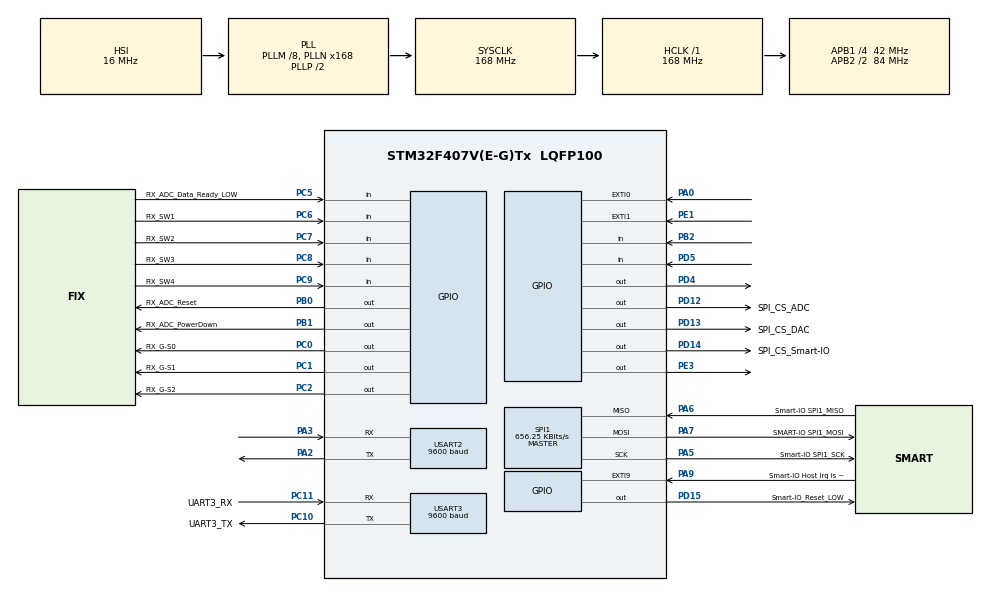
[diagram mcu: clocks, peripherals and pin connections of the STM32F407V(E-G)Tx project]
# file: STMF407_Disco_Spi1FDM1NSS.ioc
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Mcu.Family=STM32F4
Mcu.Name=STM32F407V(E-G)Tx
Mcu.Package=LQFP100
NVIC.EXTI0_IRQn=true\:0\:0\:false\:true\:true\:1\:true
NVIC.EXTI1_IRQn=true\:0\:0\:false\:true\:true\:2\:true
NVIC.PriorityGroup=NVIC_PRIORITYGROUP_0
NVIC.SPI1_IRQn=true\:0\:0\:false\:true\:true\:4\:true
NVIC.TIM2_IRQn=true\:0\:0\:false\:true\:true\:3\:true
PA0-WKUP.GPIO_ModeDefaultEXTI=GPIO_MODE_IT_RISING
PA0-WKUP.GPIO_PuPd=GPIO_NOPULL
PA0-WKUP.Signal=GPXTI0
PA10.GPIO_Mode=GPIO_MODE_AF_PP
PA10.GPIO_PuPd=GPIO_NOPULL
PA10.GPIO_Speed=GPIO_SPEED_FREQ_VERY_HIGH
PA10.Signal=USB_OTG_FS_ID
PA11.GPIO_Mode=GPIO_MODE_AF_PP
PA11.GPIO_PuPd=GPIO_NOPULL
PA11.GPIO_Speed=GPIO_SPEED_FREQ_VERY_HIGH
PA11.Signal=USB_OTG_FS_DM
PA12.GPIO_Mode=GPIO_MODE_AF_PP
PA12.GPIO_PuPd=GPIO_NOPULL
PA12.GPIO_Speed=GPIO_SPEED_FREQ_VERY_HIGH
PA12.Signal=USB_OTG_FS_DP
PA13.GPIO_Label=SerialWireDebug_IO
PA13.Mode=Serial_Wire
PA13.Signal=SYS_JTMS-SWDIO
PA14.GPIO_Label=SerialWireDebug_CLK
PA14.Mode=Serial_Wire
PA14.Signal=SYS_JTCK-SWCLK
PA15.Signal=S_TIM2_CH1_ETR
PA2.Mode=Asynchronous
PA2.Signal=USART2_TX
PA3.Mode=Asynchronous
PA3.Signal=USART2_RX
PA4.GPIO_Mode=GPIO_MODE_AF_PP
PA4.GPIO_PuPd=GPIO_NOPULL
PA4.GPIO_Speed=GPIO_SPEED_FREQ_LOW
PA4.Signal=I2S3_WS
PA5.GPIO_Label=Smart-IO SPI1_SCK
PA5.Mode=Full_Duplex_Master
PA5.Signal=SPI1_SCK
PA6.GPIO_Label=Smart-IO SPI1_MISO
PA6.GPIO_Mode=GPIO_MODE_AF_PP
PA6.GPIO_PuPd=GPIO_NOPULL
PA6.GPIO_Speed=GPIO_SPEED_FREQ_VERY_HIGH
PA6.Mode=Full_Duplex_Master
PA6.Signal=SPI1_MISO
PA7.GPIO_Label=SMART-IO SPI1_MOSI
PA7.GPIO_Mode=GPIO_MODE_AF_PP
PA7.GPIO_PuPd=GPIO_NOPULL
PA7.GPIO_Speed=GPIO_SPEED_FREQ_VERY_HIGH
PA7.Mode=Full_Duplex_Master
PA7.Signal=SPI1_MOSI
PA9.GPIO_Label=Smart-IO Host Irq is LOW
PA9.GPIO_ModeDefaultEXTI=GPIO_MODE_IT_RISING
PA9.Signal=GPXTI9
PB0.GPIO_Label=FIX_ADC_Reset
PB0.Signal=GPIO_Output
PB1.GPIO_Label=FIX_ADC_PowerDown
PB1.Signal=GPIO_Output
PB10.GPIO_Mode=GPIO_MODE_AF_PP
PB10.GPIO_PuPd=GPIO_NOPULL
PB10.GPIO_Speed=GPIO_SPEED_FREQ_LOW
PB10.Signal=I2S2_CK
PB11.Signal=I2C2_SDA
PB2.GPIO_Mode=GPIO_MODE_INPUT
PB2.GPIO_PuPd=GPIO_NOPULL
PB2.Signal=GPIO_Input
PB3.GPIO_Label=SerialWireDebug_SWO
PB3.Signal=SYS_JTDO-SWO
PB4.Signal=SYS_JTRST
PB6.Signal=I2C1_SCL
PB7.Signal=I2C1_SDA
PC0.GPIO_Label=FIX_G-S0
PC0.GPIO_ModeDefaultOutputPP=GPIO_MODE_OUTPUT_PP
PC0.GPIO_PuPd=GPIO_NOPULL
PC0.GPIO_Speed=GPIO_SPEED_FREQ_LOW
PC0.PinState=GPIO_PIN_RESET
PC0.Signal=GPIO_Output
PC1.GPIO_Label=FIX_G-S1
PC1.Signal=GPIO_Output
PC10.GPIO_Label=UART3_TX
PC10.Mode=Asynchronous
PC10.Signal=USART3_TX
PC11.GPIO_Label=UART3_RX
PC11.Mode=Asynchronous
PC11.Signal=USART3_RX
PC12.GPIO_Mode=GPIO_MODE_AF_PP
PC12.GPIO_PuPd=GPIO_NOPULL
PC12.GPIO_Speed=GPIO_SPEED_FREQ_LOW
PC12.Signal=I2S3_SD
PC2.GPIO_Label=FIX_G-S2
PC2.Signal=GPIO_Output
PC3.GPIO_Mode=GPIO_MODE_AF_PP
PC3.GPIO_PuPd=GPIO_NOPULL
PC3.GPIO_Speed=GPIO_SPEED_FREQ_LOW
PC3.Signal=I2S2_SD
PC5.GPIO_Label=FIX_ADC_Data_Ready_LOW
PC5.Signal=GPIO_Input
PC6.GPIO_Label=FIX_SW1
PC6.Signal=GPIO_Input
PC7.GPIO_Label=FIX_SW2
PC7.Signal=GPIO_Input
PC8.GPIO_Label=FIX_SW3
PC8.Signal=GPIO_Input
PC9.GPIO_Label=FIX_SW4
PC9.Signal=GPIO_Input
PD12.GPIO_Label=SPI_CS_ADC
PD12.GPIO_ModeDefaultOutputPP=GPIO_MODE_OUTPUT_PP
PD12.GPIO_PuPd=GPIO_NOPULL
PD12.GPIO_Speed=GPIO_SPEED_FREQ_LOW
PD12.PinState=GPIO_PIN_RESET
PD12.Signal=GPIO_Output
PD13.GPIO_Label=SPI_CS_DAC
PD13.GPIO_ModeDefaultOutputPP=GPIO_MODE_OUTPUT_PP
PD13.GPIO_PuPd=GPIO_NOPULL
PD13.GPIO_Speed=GPIO_SPEED_FREQ_LOW
PD13.PinState=GPIO_PIN_RESET
PD13.Signal=GPIO_Output
PD14.GPIO_Label=SPI_CS_Smart-IO
PD14.GPIO_ModeDefaultOutputPP=GPIO_MODE_OUTPUT_PP
PD14.GPIO_PuPd=GPIO_NOPULL
PD14.GPIO_Speed=GPIO_SPEED_FREQ_LOW
PD14.PinState=GPIO_PIN_RESET
PD14.Signal=GPIO_Output
PD15.GPIO_Label=Smart-IO_Reset_LOW
PD15.GPIO_ModeDefaultOutputPP=GPIO_MODE_OUTPUT_PP
PD15.GPIO_PuPd=GPIO_NOPULL
PD15.GPIO_Speed=GPIO_SPEED_FREQ_LOW
PD15.PinState=GPIO_PIN_SET
PD15.Signal=GPIO_Output
PD4.GPIO_ModeDefaultOutputPP=GPIO_MODE_OUTPUT_PP
PD4.GPIO_PuPd=GPIO_NOPULL
PD4.GPIO_Speed=GPIO_SPEED_FREQ_LOW
PD4.PinState=GPIO_PIN_RESET
PD4.Signal=GPIO_Output
PD5.GPIO_Mode=GPIO_MODE_INPUT
PD5.GPIO_PuPd=GPIO_NOPULL
PD5.Signal=GPIO_Input
PE1.GPIO_ModeDefaultEXTI=GPIO_MODE_IT_RISING
PE1.GPIO_PuPd=GPIO_NOPULL
PE1.Signal=GPXTI1
PE3.GPIO_ModeDefaultOutputPP=GPIO_MODE_OUTPUT_PP
PE3.GPIO_PuPd=GPIO_NOPULL
PE3.GPIO_Speed=GPIO_SPEED_FREQ_LOW
PE3.PinState=GPIO_PIN_RESET
PE3.Signal=GPIO_Output
PH0-OSC_IN.Signal=RCC_OSC_IN
PH1-OSC_OUT.Signal=RCC_OSC_OUT
ProjectManager.HeapSize=0x200
ProjectManager.StackSize=0x400
ProjectManager.TargetToolchain=EWARM
RCC.48MHZClocksFreq_Value=48000000
RCC.AHBFreq_Value=168000000
RCC.APB1CLKDivider=RCC_HCLK_DIV4
RCC.APB1Freq_Value=42000000
RCC.APB1TimFreq_Value=84000000
RCC.APB2CLKDivider=RCC_HCLK_DIV2
RCC.APB2Freq_Value=84000000
RCC.APB2TimFreq_Value=168000000
RCC.CortexFreq_Value=168000000
RCC.HCLKFreq_Value=168000000
RCC.HSE_VALUE=8000000
RCC.HSI_VALUE=16000000
RCC.LSE_VALUE=32768
RCC.PLLM=8
RCC.PLLN=168
RCC.PLLQ=7
RCC.SYSCLKFreq_VALUE=168000000
RCC.SYSCLKSource=RCC_SYSCLKSOURCE_PLLCLK
RCC.VCOOutputFreq_Value=336000000
SH.S_TIM2_CH1_ETR.0=TIM2_CH1
SPI1.BaudRatePrescaler=SPI_BAUDRATEPRESCALER_128
SPI1.CalculateBaudRate=656.25 KBits/s
SPI1.Direction=SPI_DIRECTION_2LINES
SPI1.Mode=SPI_MODE_MASTER
SPI1.VirtualType=VM_MASTER
TIM2.ClockDivision=TIM_CLOCKDIVISION_DIV4
TIM2.Prescaler=0
USART2.BaudRate=9600
USART2.VirtualMode=VM_ASYNC
USART3.BaudRate=9600
USART3.VirtualMode=VM_ASYNC
VP_RTC_VS_RTC_Activate.Mode=RTC_Enabled
VP_RTC_VS_RTC_Calendar.Mode=RTC_Calendar
VP_TIM1_VS_ClockSourceINT.Mode=Internal
VP_TIM2_VS_ClockSourceINT.Mode=Internal
VP_TIM3_VS_ClockSourceINT.Mode=Internal
board=STM32F4DISCOVERY

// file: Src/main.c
/**
  ******************************************************************************
  * @file           : main.c
  * @brief          : Main program body
  ******************************************************************************
  ** This notice applies to any and all portions of this file
  * that are not between comment pairs USER CODE BEGIN and
  * USER CODE END. Other portions of this file, whether
  * inserted by the user or by software development tools
  * are owned by their respective copyright owners.
  *
  * COPYRIGHT(c) 2018 STMicroelectronics
  *
  * Redistribution and use in source and binary forms, with or without modification,
  * are permitted provided that the following conditions are met:
  *   1. Redistributions of source code must retain the above copyright notice,
  *      this list of conditions and the following disclaimer.
  *   2. Redistributions in binary form must reproduce the above copyright notice,
  *      this list of conditions and the following disclaimer in the documentation
  *      and/or other materials provided with the distribution.
  *   3. Neither the name of STMicroelectronics nor the names of its contributors
  *      may be used to endorse or promote products derived from this software
  *      without specific prior written permission.
  *
  * THIS SOFTWARE IS PROVIDED BY THE COPYRIGHT HOLDERS AND CONTRIBUTORS "AS IS"
  * AND ANY EXPRESS OR IMPLIED WARRANTIES, INCLUDING, BUT NOT LIMITED TO, THE
  * IMPLIED WARRANTIES OF MERCHANTABILITY AND FITNESS FOR A PARTICULAR PURPOSE ARE
  * DISCLAIMED. IN NO EVENT SHALL THE COPYRIGHT HOLDER OR CONTRIBUTORS BE LIABLE
  * FOR ANY DIRECT, INDIRECT, INCIDENTAL, SPECIAL, EXEMPLARY, OR CONSEQUENTIAL
  * DAMAGES (INCLUDING, BUT NOT LIMITED TO, PROCUREMENT OF SUBSTITUTE GOODS OR
  * SERVICES; LOSS OF USE, DATA, OR PROFITS; OR BUSINESS INTERRUPTION) HOWEVER
  * CAUSED AND ON ANY THEORY OF LIABILITY, WHETHER IN CONTRACT, STRICT LIABILITY,
  * OR TORT (INCLUDING NEGLIGENCE OR OTHERWISE) ARISING IN ANY WAY OUT OF THE USE
  * OF THIS SOFTWARE, EVEN IF ADVISED OF THE POSSIBILITY OF SUCH DAMAGE.
  *
  ******************************************************************************
  */
#include "main.h"
#include "stm32f4xx_hal.h"
#include "rtc.h"
#include "spi.h"
#include "tim.h"
#include "usart.h"
#include "gpio.h"

/* USER CODE BEGIN Includes */
//#include "Smart-IO.main
/* USER CODE END Includes */

/* USER CODE BEGIN PV */
/* Private variables ---------------------------------------------------------*/
uint8_t txArray_9[9] = "abcTest\n\r";
/* USER CODE END PV */

void SystemClock_Config(void);
static void MX_NVIC_Init(void);

/* USER CODE BEGIN PFP */
/* Private function prototypes -----------------------------------------------*/

/* USER CODE END PFP */

int main(void)
{
  /* USER CODE BEGIN 1 */
//FISH_STM32F4_CONFIG_DEFINES.h
  /* USER CODE END 1 */

  /* MCU Configuration----------------------------------------------------------*/

  /* Reset of all peripherals, Initializes the Flash interface and the Systick. */
  HAL_Init();

  /* Configure the system clock */
  SystemClock_Config();

  /* USER CODE BEGIN SysInit */
  // In the MX_"PERIPH"_Init() calls below:

  // MX_USART2_UART_Init(); Creates UART_HandleTypeDef huart2; Smart_IO commamds
  // MX_USART3_UART_Init(); Creates UART_HandleTypeDef huart3; FISH

  // MX_SPI1_Init(); Creates SPI_HandleTypeDef  hspi;
  // It's name can't be changed - overwritten by CubeMX.
  /*
      I have to verify settings and make my own and call after if so.
      And verify clock is giving me the required Smart-IO Clock and
      the other spi devices needs.
      STM NSS is not used. SPI chip select is software managed.
      NSS on SPI1 forces SWD vs JTAG.
  */

  /* USER CODE END SysInit */

  /* Initialize all configured peripherals */
  MX_GPIO_Init();
  MX_USART3_UART_Init();
  MX_SPI1_Init();
  MX_TIM1_Init();
  MX_TIM2_Init();
  MX_TIM3_Init();
  MX_RTC_Init();
  MX_USART2_UART_Init();

  /* Initialize interrupts */
  MX_NVIC_Init();
  /* USER CODE BEGIN 2 */
/*

  * @brief  Sends an amount of data in non blocking mode.
  * @param  huart pointer to a UART_HandleTypeDef structure that contains
  *                the configuration information for the specified UART module.
  * @param  pData Pointer to data buffer
  * @param  Size Amount of data to be sent
  * @retval HAL status
HAL_StatusTypeDef HAL_UART_Transmit_IT(UART_HandleTypeDef *huart, uint8_t *pData, uint16_t Size)
*/
  HAL_UART_Transmit_IT(&huart3, "Test\n\r", 6);
  HAL_UART_Transmit_IT(&huart3, txArray_9, 9);
  Smart_IO_main();

/* (@) From stm32f4xx_hal_spi.c: The max SPI frequency depend on SPI data size (8bits, 16bits),
       SPI mode(2 Lines fullduplex, 2 lines RxOnly, 1 line TX/RX) and Process mode (Polling, IT, DMA).
   (@)
        (+@) TX/RX processes are HAL_SPI_TransmitReceive(), HAL_SPI_TransmitReceive_IT() and HAL_SPI_TransmitReceive_DMA()
        (+@) RX processes are HAL_SPI_Receive(), HAL_SPI_Receive_IT() and HAL_SPI_Receive_DMA()
        (+@) TX processes are HAL_SPI_Transmit(), HAL_SPI_Transmit_IT() and HAL_SPI_Transmit_DMA()
*/
/* (@) If we use the F4 Discovery board use the LED's for debug/system status */
/* (#) Declare a SPI_HandleTypeDef handle structure, for example: */
/*        SPI_HandleTypeDef  hspi;
          or
          SPI_HandleTypeDef  SmartIO_hal_spi_handle;
*/
//  HAL_SPI_Transmit(SPI_HandleTypeDef *hspi, uint8_t *pData, uint16_t Size, uint32_t Timeout)

  /* USER CODE END 2 */

  /* Infinite loop */
  while (1)
  {

  }

}

void SystemClock_Config(void)
{

  RCC_OscInitTypeDef RCC_OscInitStruct;
  RCC_ClkInitTypeDef RCC_ClkInitStruct;
  RCC_PeriphCLKInitTypeDef PeriphClkInitStruct;

    /**Configure the main internal regulator output voltage
    */
  __HAL_RCC_PWR_CLK_ENABLE();

  __HAL_PWR_VOLTAGESCALING_CONFIG(PWR_REGULATOR_VOLTAGE_SCALE1);

    /**Initializes the CPU, AHB and APB busses clocks
    */
  RCC_OscInitStruct.OscillatorType = RCC_OSCILLATORTYPE_HSI|RCC_OSCILLATORTYPE_LSI;
  RCC_OscInitStruct.HSIState = RCC_HSI_ON;
  RCC_OscInitStruct.HSICalibrationValue = 16;
  RCC_OscInitStruct.LSIState = RCC_LSI_ON;
  RCC_OscInitStruct.PLL.PLLState = RCC_PLL_ON;
  RCC_OscInitStruct.PLL.PLLSource = RCC_PLLSOURCE_HSI;
  RCC_OscInitStruct.PLL.PLLM = 8;
  RCC_OscInitStruct.PLL.PLLN = 168;
  RCC_OscInitStruct.PLL.PLLP = RCC_PLLP_DIV2;
  RCC_OscInitStruct.PLL.PLLQ = 7;
  if (HAL_RCC_OscConfig(&RCC_OscInitStruct) != HAL_OK)
  {
    _Error_Handler(__FILE__, __LINE__);
  }

    /**Initializes the CPU, AHB and APB busses clocks
    */
  RCC_ClkInitStruct.ClockType = RCC_CLOCKTYPE_HCLK|RCC_CLOCKTYPE_SYSCLK
                              |RCC_CLOCKTYPE_PCLK1|RCC_CLOCKTYPE_PCLK2;
  RCC_ClkInitStruct.SYSCLKSource = RCC_SYSCLKSOURCE_PLLCLK;
  RCC_ClkInitStruct.AHBCLKDivider = RCC_SYSCLK_DIV1;
  RCC_ClkInitStruct.APB1CLKDivider = RCC_HCLK_DIV4;
  RCC_ClkInitStruct.APB2CLKDivider = RCC_HCLK_DIV2;

  if (HAL_RCC_ClockConfig(&RCC_ClkInitStruct, FLASH_LATENCY_5) != HAL_OK)
  {
    _Error_Handler(__FILE__, __LINE__);
  }

  PeriphClkInitStruct.PeriphClockSelection = RCC_PERIPHCLK_RTC;
  PeriphClkInitStruct.RTCClockSelection = RCC_RTCCLKSOURCE_LSI;
  if (HAL_RCCEx_PeriphCLKConfig(&PeriphClkInitStruct) != HAL_OK)
  {
    _Error_Handler(__FILE__, __LINE__);
  }

    /**Configure the Systick interrupt time
    */
  HAL_SYSTICK_Config(HAL_RCC_GetHCLKFreq()/1000);

    /**Configure the Systick
    */
  HAL_SYSTICK_CLKSourceConfig(SYSTICK_CLKSOURCE_HCLK);

  /* SysTick_IRQn interrupt configuration */
  HAL_NVIC_SetPriority(SysTick_IRQn, 0, 0);
}

/**
  * @brief NVIC Configuration.
  * @retval None
  */
static void MX_NVIC_Init(void)
{
  /* EXTI0_IRQn interrupt configuration */
  HAL_NVIC_SetPriority(EXTI0_IRQn, 0, 0);
  HAL_NVIC_EnableIRQ(EXTI0_IRQn);
  /* EXTI1_IRQn interrupt configuration */
  HAL_NVIC_SetPriority(EXTI1_IRQn, 0, 0);
  HAL_NVIC_EnableIRQ(EXTI1_IRQn);
  /* TIM2_IRQn interrupt configuration */
  HAL_NVIC_SetPriority(TIM2_IRQn, 0, 0);
  HAL_NVIC_EnableIRQ(TIM2_IRQn);
  /* SPI1_IRQn interrupt configuration */
  HAL_NVIC_SetPriority(SPI1_IRQn, 0, 0);
  HAL_NVIC_EnableIRQ(SPI1_IRQn);
}

void _Error_Handler(char *file, int line)
{
  while(1)
  {
  }
}

/************************ (C) COPYRIGHT STMicroelectronics *****END OF FILE****/
